# STM32L4x3 register map
File version: 1.3
CPU: CM4 r1p0, little endian, no MPU, no FPU, 3 interrupt priority bits
Registers are 32-bit, read-write, reset 0x0 unless marked. A register's access mark holds for its fields unless they carry their own. Offsets are from the block's base; [hi:lo] are bit positions.

## WWDG — System window watchdog
Base 0x40002C00
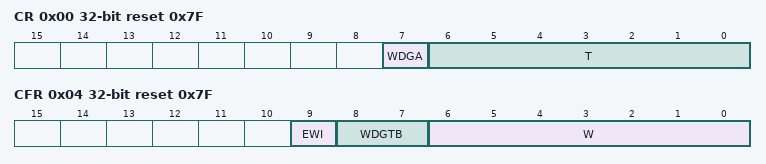
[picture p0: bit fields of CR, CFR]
0x00 CR reset 0x7F — Control register
  [7] WDGA — Activation bit
  [6:0] T — 7-bit counter (MSB to LSB)
0x04 CFR reset 0x7F — Configuration register
  [9] EWI — Early wakeup interrupt
  [8:7] WDGTB — Timer base
  [6:0] W — 7-bit window value
0x08 SR — Status register
  [0] EWIF — Early wakeup interrupt flag

## COMP — Comparator
Base 0x40010200
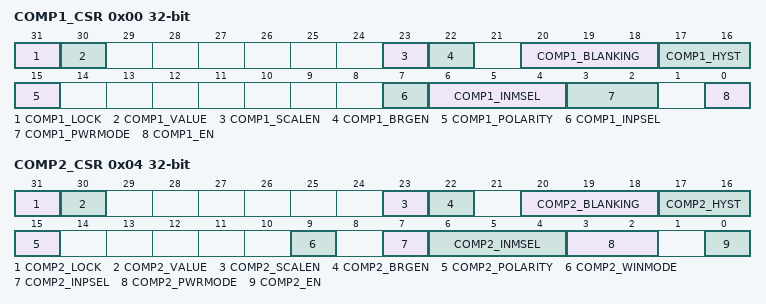
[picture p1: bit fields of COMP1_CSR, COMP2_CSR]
0x00 COMP1_CSR access per field — Comparator 1 control and status register
  [31] COMP1_LOCK wo — COMP1_CSR register lock bit
  [30] COMP1_VALUE ro — Comparator 1 output status bit
  [23] COMP1_SCALEN rw — Voltage scaler enable bit
  [22] COMP1_BRGEN rw — Scaler bridge enable
  [20:18] COMP1_BLANKING rw — Comparator 1 blanking source selection bits
  [17:16] COMP1_HYST rw — Comparator 1 hysteresis selection bits
  [15] COMP1_POLARITY rw — Comparator 1 polarity selection bit
  [7] COMP1_INPSEL rw — Comparator1 input plus selection bit
  [6:4] COMP1_INMSEL rw — Comparator 1 Input Minus connection configuration bit
  [3:2] COMP1_PWRMODE rw — Power Mode of the comparator 1
  [0] COMP1_EN rw — Comparator 1 enable bit
0x04 COMP2_CSR access per field — Comparator 2 control and status register
  [31] COMP2_LOCK wo — COMP2_CSR register lock bit
  [30] COMP2_VALUE ro — Comparator 2 output status bit
  [23] COMP2_SCALEN rw — Voltage scaler enable bit
  [22] COMP2_BRGEN rw — Scaler bridge enable
  [20:18] COMP2_BLANKING rw — Comparator 2 blanking source selection bits
  [17:16] COMP2_HYST rw — Comparator 2 hysteresis selection bits
  [15] COMP2_POLARITY rw — Comparator 2 polarity selection bit
  [9] COMP2_WINMODE rw — Windows mode selection bit
  [7] COMP2_INPSEL rw — Comparator 2 Input Plus connection configuration bit
  [6:4] COMP2_INMSEL rw — Comparator 2 Input Minus connection configuration bit
  [3:2] COMP2_PWRMODE rw — Power Mode of the comparator 2
  [0] COMP2_EN rw — Comparator 2 enable bit

## FIREWALL
Base 0x40011C00
0x00 CSSA — Code segment start address
  [23:8] ADD — code segment start address
0x04 CSL — Code segment length
  [21:8] LENG — code segment length
0x08 NVDSSA — Non-volatile data segment start address
  [23:8] ADD
0x0C NVDSL — Non-volatile data segment length
  [21:8] LENG
0x10 VDSSA — Volatile data segment start address
  [15:6] ADD
0x14 VDSL — Volatile data segment length
  [15:6] LENG — Non-volatile data segment length
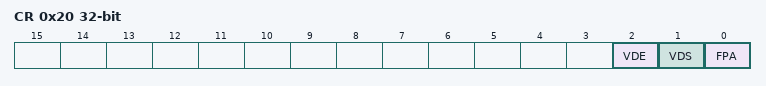
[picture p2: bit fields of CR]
0x20 CR — Configuration register
  [2] VDE — Volatile data execution
  [1] VDS — Volatile data shared
  [0] FPA — Firewall pre alarm

## RNG — Random number generator
Base 0x50060800
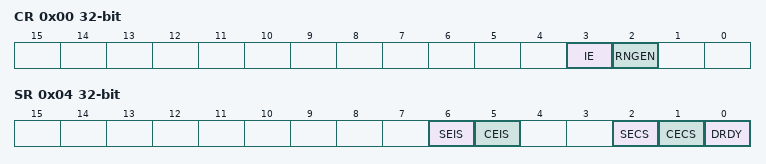
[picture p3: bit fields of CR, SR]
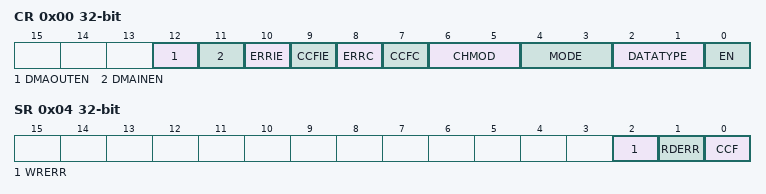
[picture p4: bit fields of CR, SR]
0x00 CR — control register
  [3] IE — Interrupt enable
  [2] RNGEN — Random number generator enable
0x04 SR access per field — status register
  [6] SEIS rw — Seed error interrupt status
  [5] CEIS rw — Clock error interrupt status
  [2] SECS ro — Seed error current status
  [1] CECS ro — Clock error current status
  [0] DRDY ro — Data ready
0x08 DR ro — data register
  [31:0] RNDATA — Random data

## AES — Advanced encryption standard hardware accelerator
Base 0x50060000
0x00 CR — control register
  [12] DMAOUTEN — Enable DMA management of data output phase
  [11] DMAINEN — Enable DMA management of data input phase
  [10] ERRIE — Error interrupt enable
  [9] CCFIE — CCF flag interrupt enable
  [8] ERRC — Error clear
  [7] CCFC — Computation Complete Flag Clear
  [6:5] CHMOD — AES chaining mode
  [4:3] MODE — AES operating mode
  [2:1] DATATYPE — Data type selection (for data in and data out to/from the cryptographic block)
  [0] EN — AES enable
0x04 SR ro — status register
  [2] WRERR — Write error flag
  [1] RDERR — Read error flag
  [0] CCF — Computation complete flag
0x08 DINR — data input register
  [31:0] AES_DINR — Data Input Register
0x0C DOUTR ro — data output register
  [31:0] AES_DOUTR — Data output register
0x10 KEYR0 — key register 0
  [31:0] AES_KEYR0 — Data Output Register (LSB key [31:0])
0x14 KEYR1 — key register 1
  [31:0] AES_KEYR1 — AES key register (key [63:32])
0x18 KEYR2 — key register 2
  [31:0] AES_KEYR2 — AES key register (key [95:64])
0x1C KEYR3 — key register 3
  [31:0] AES_KEYR3 — AES key register (MSB key [127:96])
0x20 IVR0 — initialization vector register 0
  [31:0] AES_IVR0 — initialization vector register (LSB IVR [31:0])
0x24 IVR1 — initialization vector register 1
  [31:0] AES_IVR1 — Initialization Vector Register (IVR [63:32])
0x28 IVR2 — initialization vector register 2
  [31:0] AES_IVR2 — Initialization Vector Register (IVR [95:64])
0x2C IVR3 — initialization vector register 3
  [31:0] AES_IVR3 — Initialization Vector Register (MSB IVR [127:96])
